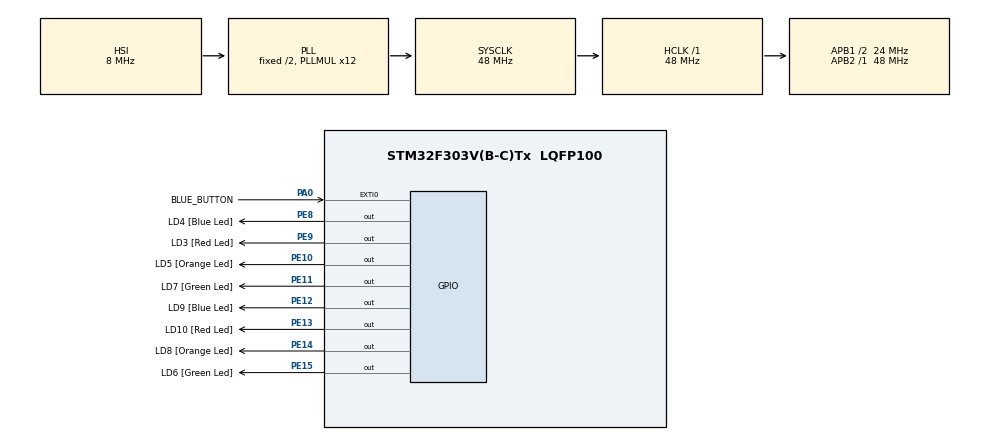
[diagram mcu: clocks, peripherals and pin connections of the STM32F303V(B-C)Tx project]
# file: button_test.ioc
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Mcu.Family=STM32F3
Mcu.Name=STM32F303V(B-C)Tx
Mcu.Package=LQFP100
NVIC.EXTI0_IRQn=true\:0\:1\:false\:false\:true\:true\:true
NVIC.PriorityGroup=NVIC_PRIORITYGROUP_0
NVIC.TIM1_UP_TIM16_IRQn=true\:0\:0\:false\:false\:true\:true\:true
NVIC.TIM7_IRQn=true\:0\:0\:false\:false\:true\:true\:true
PA0.GPIO_Label=BLUE_BUTTON
PA0.Signal=GPXTI0
PA13.GPIO_Label=SWDIO
PA13.Mode=Serial_Wire
PA13.Signal=SYS_JTMS-SWDIO
PA14.GPIO_Label=SWCLK
PA14.Mode=Serial_Wire
PA14.Signal=SYS_JTCK-SWCLK
PB3.GPIO_Label=SWO
PB3.Signal=SYS_JTDO-TRACESWO
PE10.GPIO_Label=LD5 [Orange Led]
PE10.Signal=GPIO_Output
PE11.GPIO_Label=LD7 [Green Led]
PE11.Signal=GPIO_Output
PE12.GPIO_Label=LD9 [Blue Led]
PE12.Signal=GPIO_Output
PE13.GPIO_Label=LD10 [Red Led]
PE13.Signal=GPIO_Output
PE14.GPIO_Label=LD8 [Orange Led]
PE14.Signal=GPIO_Output
PE15.GPIO_Label=LD6 [Green Led]
PE15.Signal=GPIO_Output
PE8.GPIO_Label=LD4 [Blue Led]
PE8.Signal=GPIO_Output
PE9.GPIO_Label=LD3 [Red Led]
PE9.Signal=GPIO_Output
ProjectManager.HeapSize=0x200
ProjectManager.StackSize=0x400
ProjectManager.TargetToolchain=MDK-ARM V5.27
RCC.AHBFreq_Value=48000000
RCC.APB1CLKDivider=RCC_HCLK_DIV2
RCC.APB1Freq_Value=24000000
RCC.APB1TimFreq_Value=48000000
RCC.APB2Freq_Value=48000000
RCC.APB2TimFreq_Value=48000000
RCC.CortexFreq_Value=48000000
RCC.HCLKFreq_Value=48000000
RCC.HSE_VALUE=8000000
RCC.HSI_VALUE=8000000
RCC.LSE_VALUE=32768
RCC.PLLMUL=RCC_PLL_MUL12
RCC.SYSCLKFreq_VALUE=48000000
RCC.SYSCLKSourceVirtual=RCC_SYSCLKSOURCE_PLLCLK
RCC.USBFreq_Value=48000000
TIM16.AutoReloadPreload=TIM_AUTORELOAD_PRELOAD_ENABLE
TIM16.Period=59999
TIM16.Prescaler=599
TIM7.AutoReloadPreload=TIM_AUTORELOAD_PRELOAD_ENABLE
TIM7.Period=59999
TIM7.Prescaler=7
VP_TIM16_VS_ClockSourceINT.Mode=Enable_Timer
VP_TIM7_VS_ClockSourceINT.Mode=Enable_Timer
board=STM32F3DISCOVERY

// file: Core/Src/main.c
/* USER CODE BEGIN Header */
/**
  ******************************************************************************
  * @file           : main.c
  * @brief          : Main program body
  ******************************************************************************
  * @attention
  *
  * <h2><center>&copy; Copyright (c) 2020 STMicroelectronics.
  * All rights reserved.</center></h2>
  *
  * This software component is licensed by ST under BSD 3-Clause license,
  * the "License"; You may not use this file except in compliance with the
  * License. You may obtain a copy of the License at:
  *                        opensource.org/licenses/BSD-3-Clause
  *
  ******************************************************************************
  */
/* USER CODE END Header */
#include "main.h"

/* USER CODE BEGIN Includes */
#include "button.h"
#include "version.h"
/* USER CODE END Includes */

TIM_HandleTypeDef htim7;
TIM_HandleTypeDef htim16;

/* USER CODE BEGIN PV */
uint8_t versionBuffer[100] = {0};
/* USER CODE END PV */

void SystemClock_Config(void);
static void MX_GPIO_Init(void);
static void MX_TIM7_Init(void);
static void MX_TIM16_Init(void);

int main(void)
{

  /* MCU Configuration--------------------------------------------------------*/

  /* Reset of all peripherals, Initializes the Flash interface and the Systick. */
  HAL_Init();

  /* Configure the system clock */
  SystemClock_Config();

  /* Initialize all configured peripherals */
  MX_GPIO_Init();
  MX_TIM7_Init();
  MX_TIM16_Init();
  /* USER CODE BEGIN 2 */

  uint8_t numberOfPresses = 0;
  //uint8_t dummy = 0;

  version_get_info(versionBuffer, sizeof(versionBuffer)/sizeof(versionBuffer[0]));

  /* USER CODE END 2 */

  /* Infinite loop */
  /* USER CODE BEGIN WHILE */
  while (1)
  {
    if(button_has_event())
    {
       numberOfPresses = button_get_press_count();

       //dummy = numberOfPresses;
    }
    /* USER CODE END WHILE */

  }
}

void SystemClock_Config(void)
{
  RCC_OscInitTypeDef RCC_OscInitStruct = {0};
  RCC_ClkInitTypeDef RCC_ClkInitStruct = {0};

  /** Initializes the RCC Oscillators according to the specified parameters
  * in the RCC_OscInitTypeDef structure.
  */
  RCC_OscInitStruct.OscillatorType = RCC_OSCILLATORTYPE_HSI;
  RCC_OscInitStruct.HSIState = RCC_HSI_ON;
  RCC_OscInitStruct.HSICalibrationValue = RCC_HSICALIBRATION_DEFAULT;
  RCC_OscInitStruct.PLL.PLLState = RCC_PLL_ON;
  RCC_OscInitStruct.PLL.PLLSource = RCC_PLLSOURCE_HSI;
  RCC_OscInitStruct.PLL.PLLMUL = RCC_PLL_MUL12;
  if (HAL_RCC_OscConfig(&RCC_OscInitStruct) != HAL_OK)
  {
    Error_Handler();
  }
  /** Initializes the CPU, AHB and APB buses clocks
  */
  RCC_ClkInitStruct.ClockType = RCC_CLOCKTYPE_HCLK|RCC_CLOCKTYPE_SYSCLK
                              |RCC_CLOCKTYPE_PCLK1|RCC_CLOCKTYPE_PCLK2;
  RCC_ClkInitStruct.SYSCLKSource = RCC_SYSCLKSOURCE_PLLCLK;
  RCC_ClkInitStruct.AHBCLKDivider = RCC_SYSCLK_DIV1;
  RCC_ClkInitStruct.APB1CLKDivider = RCC_HCLK_DIV2;
  RCC_ClkInitStruct.APB2CLKDivider = RCC_HCLK_DIV1;

  if (HAL_RCC_ClockConfig(&RCC_ClkInitStruct, FLASH_LATENCY_1) != HAL_OK)
  {
    Error_Handler();
  }
}

static void MX_TIM7_Init(void)
{

  TIM_MasterConfigTypeDef sMasterConfig = {0};

  htim7.Instance = TIM7;
  htim7.Init.Prescaler = 7;
  htim7.Init.CounterMode = TIM_COUNTERMODE_UP;
  htim7.Init.Period = 59999;
  htim7.Init.AutoReloadPreload = TIM_AUTORELOAD_PRELOAD_ENABLE;
  if (HAL_TIM_Base_Init(&htim7) != HAL_OK)
  {
    Error_Handler();
  }
  sMasterConfig.MasterOutputTrigger = TIM_TRGO_RESET;
  sMasterConfig.MasterSlaveMode = TIM_MASTERSLAVEMODE_DISABLE;
  if (HAL_TIMEx_MasterConfigSynchronization(&htim7, &sMasterConfig) != HAL_OK)
  {
    Error_Handler();
  }
  /* USER CODE BEGIN TIM7_Init 2 */
  //HAL_TIM_Base_Start_IT(&htim7);
  __HAL_TIM_CLEAR_FLAG(&htim7, TIM_FLAG_UPDATE);
  /* USER CODE END TIM7_Init 2 */

}

static void MX_TIM16_Init(void)
{

  htim16.Instance = TIM16;
  htim16.Init.Prescaler = 599;
  htim16.Init.CounterMode = TIM_COUNTERMODE_UP;
  htim16.Init.Period = 59999;
  htim16.Init.ClockDivision = TIM_CLOCKDIVISION_DIV1;
  htim16.Init.RepetitionCounter = 0;
  htim16.Init.AutoReloadPreload = TIM_AUTORELOAD_PRELOAD_ENABLE;
  if (HAL_TIM_Base_Init(&htim16) != HAL_OK)
  {
    Error_Handler();
  }
  /* USER CODE BEGIN TIM16_Init 2 */
  __HAL_TIM_CLEAR_FLAG(&htim16, TIM_FLAG_UPDATE);
  /* USER CODE END TIM16_Init 2 */

}

static void MX_GPIO_Init(void)
{
  GPIO_InitTypeDef GPIO_InitStruct = {0};

  /* GPIO Ports Clock Enable */
  __HAL_RCC_GPIOA_CLK_ENABLE();
  __HAL_RCC_GPIOE_CLK_ENABLE();
  __HAL_RCC_GPIOB_CLK_ENABLE();

  /*Configure GPIO pin Output Level */
  HAL_GPIO_WritePin(GPIOE, LD4_Pin|LD3_Pin|LD5_Pin|LD7_Pin
                          |LD9_Pin|LD10_Pin|LD8_Pin|LD6_Pin, GPIO_PIN_RESET);

  /*Configure GPIO pin : BLUE_BUTTON_Pin */
  GPIO_InitStruct.Pin = BLUE_BUTTON_Pin;
  GPIO_InitStruct.Mode = GPIO_MODE_IT_RISING;
  GPIO_InitStruct.Pull = GPIO_NOPULL;
  HAL_GPIO_Init(BLUE_BUTTON_GPIO_Port, &GPIO_InitStruct);

  /*Configure GPIO pins : LD4_Pin LD3_Pin LD5_Pin LD7_Pin
                           LD9_Pin LD10_Pin LD8_Pin LD6_Pin */
  GPIO_InitStruct.Pin = LD4_Pin|LD3_Pin|LD5_Pin|LD7_Pin
                          |LD9_Pin|LD10_Pin|LD8_Pin|LD6_Pin;
  GPIO_InitStruct.Mode = GPIO_MODE_OUTPUT_PP;
  GPIO_InitStruct.Pull = GPIO_NOPULL;
  GPIO_InitStruct.Speed = GPIO_SPEED_FREQ_LOW;
  HAL_GPIO_Init(GPIOE, &GPIO_InitStruct);

  /* EXTI interrupt init*/
  HAL_NVIC_SetPriority(EXTI0_IRQn, 0, 1);
  HAL_NVIC_EnableIRQ(EXTI0_IRQn);

}

void Error_Handler(void)
{
}

/************************ (C) COPYRIGHT STMicroelectronics *****END OF FILE****/
